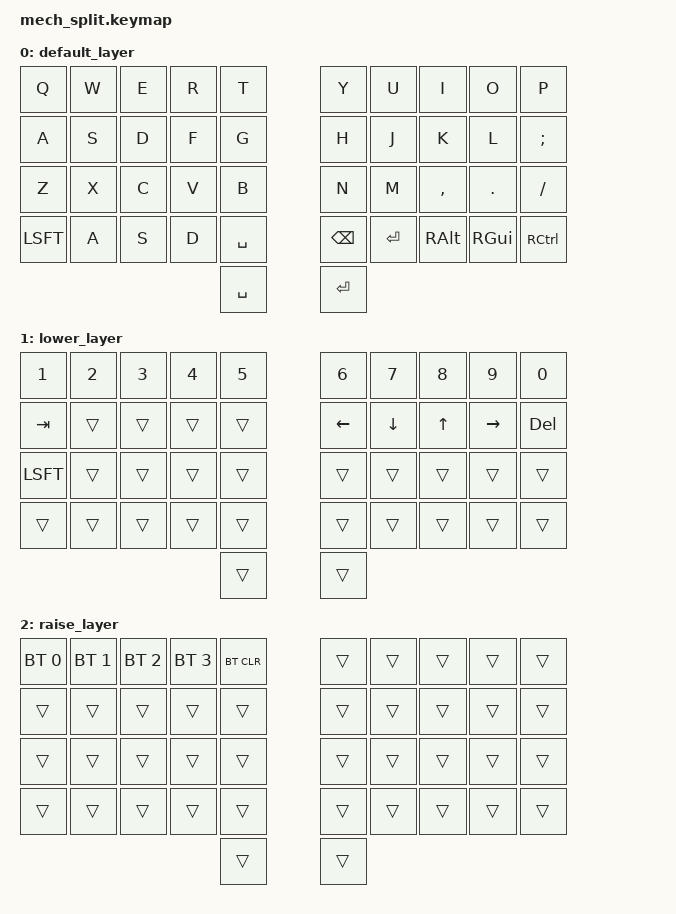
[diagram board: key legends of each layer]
#include <behaviors.dtsi>
#include <dt-bindings/zmk/keys.h>
#include <dt-bindings/zmk/bt.h>

/ {
    keymap {
        compatible = "zmk,keymap";

        default_layer {
            bindings = 
                &kp Q    &kp W    &kp E    &kp R    &kp T        &kp Y    &kp U    &kp I     &kp O    &kp P
                &kp A    &kp S    &kp D    &kp F    &kp G        &kp H    &kp J    &kp K     &kp L    &kp SEMI
                &kp Z    &kp X    &kp C    &kp V    &kp B        &kp N    &kp M    &kp COMMA &kp DOT  &kp SLASH
                &kp LSFT &kp A    &kp S    &kp D    &kp SPACE    &kp BSPC &kp RET  &kp RALT  &kp RGUI &kp RCTRL
                                                    &kp SPACE    &kp RET
            >;
        };

        lower_layer {
            bindings = 
                &kp N1   &kp N2   &kp N3   &kp N4   &kp N5       &kp N6   &kp N7   &kp N8   &kp N9   &kp N0
                &kp TAB  &trans   &trans   &trans   &trans       &kp LEFT &kp DOWN &kp UP   &kp RIGHT &kp DEL
                &kp LSFT &trans   &trans   &trans   &trans       &trans   &trans   &trans   &trans   &trans
                &trans   &trans   &trans   &trans   &trans       &trans   &trans   &trans   &trans   &trans
                                                    &trans       &trans
            >;
        };

        raise_layer {
            bindings = 
                &bt BT_SEL 0 &bt BT_SEL 1 &bt BT_SEL 2 &bt BT_SEL 3 &bt BT_CLR    &trans &trans &trans &trans &trans
                &trans       &trans       &trans       &trans       &trans         &trans &trans &trans &trans &trans
                &trans       &trans       &trans       &trans       &trans         &trans &trans &trans &trans &trans
                &trans       &trans       &trans       &trans       &trans         &trans &trans &trans &trans &trans
                                                                    &trans         &trans
            >;
        };
    };
};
